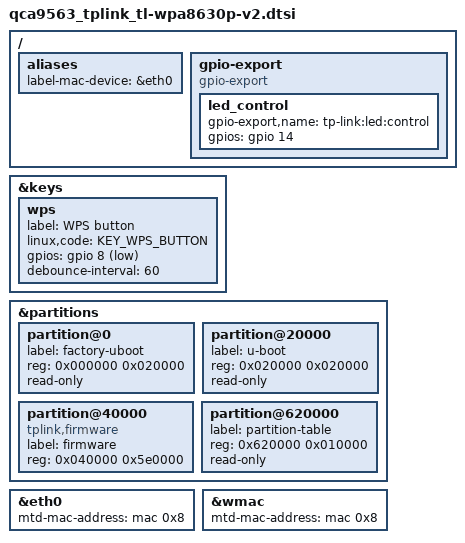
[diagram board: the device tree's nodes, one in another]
// SPDX-License-Identifier: GPL-2.0-or-later OR MIT

#include "qca9563_tplink_tl-wpa8630.dtsi"

/ {
	aliases {
		label-mac-device = &eth0;
	};

	gpio-export {
		compatible = "gpio-export";

		led_control {
			gpio-export,name = "tp-link:led:control";
			gpios = <&gpio 14 GPIO_ACTIVE_HIGH>;
		};
	};
};

&keys {
	wps {
		label = "WPS button";
		linux,code = <KEY_WPS_BUTTON>;
		gpios = <&gpio 8 GPIO_ACTIVE_LOW>;
		debounce-interval = <60>;
	};
};

&partitions {
	partition@0 {
		label = "factory-uboot";
		reg = <0x000000 0x020000>;
		read-only;
	};

	partition@20000 {
		label = "u-boot";
		reg = <0x020000 0x020000>;
		read-only;
	};

	partition@40000 {
		compatible = "tplink,firmware";
		label = "firmware";
		reg = <0x040000 0x5e0000>;
	};

	partition@620000 {
		label = "partition-table";
		reg = <0x620000 0x010000>;
		read-only;
	};
};

&eth0 {
	mtd-mac-address = <&mac 0x8>;
};

&wmac {
	mtd-mac-address = <&mac 0x8>;
};
